# PIC32CX1025SG41064 device description
Architecture: CORTEX-M4; Family: PIC32CX; Series: PIC32CXSG41
Registers are 32-bit, read-write, reset 0x0 unless marked. A register's access mark holds for its fields unless they carry their own. Offsets are from the block's base; [hi:lo] are bit positions; {n}, {i} and the like mark numbered series; 'fields as' and 'values as' point back to an identical list.

## AES — Advanced Encryption Standard
Instances: AES 0x42002400
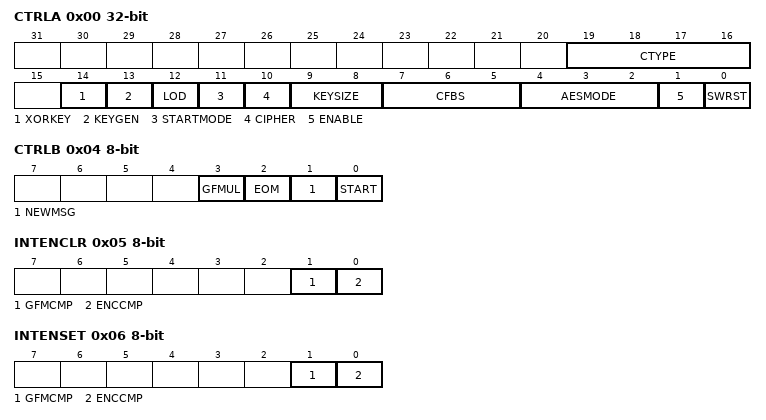
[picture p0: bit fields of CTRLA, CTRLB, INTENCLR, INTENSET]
0x00 CTRLA — Control A
  [19:16] CTYPE — Counter Measure Type
  [14] XORKEY — XOR Key Operation
    0=NONE (No effect); 1=XOR (The user keyword gets XORed with the previous keyword register content.)
  [13] KEYGEN — Last Key Generation
    0=NONE (No effect); 1=LAST (Start Computation of the last NK words of the expanded key)
  [12] LOD — Last Output Data Mode
    0=NONE (No effect); 1=LAST (Start encryption in Last Output Data mode)
  [11] STARTMODE — Start Mode Select
    0=MANUAL (Start Encryption / Decryption in Manual mode); 1=AUTO (Start Encryption / Decryption in Auto mode)
  [10] CIPHER — Cipher Mode
    0=DEC (Decryption); 1=ENC (Encryption)
  [9:8] KEYSIZE — Encryption Key Size
    0=128BIT (128-bit Key for Encryption / Decryption); 1=192BIT (192-bit Key for Encryption / Decryption); 2=256BIT (256-bit Key for Encryption / Decryption)
  [7:5] CFBS — Cipher Feedback Block Size
    0=128BIT (128-bit Input data block for Encryption/Decryption in Cipher Feedback mode); 1=64BIT (64-bit Input data block for Encryption/Decryption in Cipher Feedback mode); 2=32BIT (32-bit Input data block for Encryption/Decryption in Cipher Feedback mode); 3=16BIT (16-bit Input data block for Encryption/Decryption in Cipher Feedback mode); 4=8BIT (8-bit Input data block for Encryption/Decryption in Cipher Feedback mode)
  [4:2] AESMODE — AES Modes of operation
    0=ECB (Electronic code book mode); 1=CBC (Cipher block chaining mode); 2=OFB (Output feedback mode); 3=CFB (Cipher feedback mode); 4=COUNTER (Counter mode); 5=CCM (CCM mode); 6=GCM (Galois counter mode)
  [1] ENABLE
  [0] SWRST — Software Reset
0x04 CTRLB 8-bit — Control B
  [3] GFMUL — GF Multiplication
  [2] EOM — End of message
  [1] NEWMSG — New message
  [0] START — Start Encryption/Decryption
0x05 INTENCLR 8-bit (atomic clear) — Interrupt Enable Clear
  [1] GFMCMP — GF Multiplication Complete Interrupt Enable
  [0] ENCCMP — Encryption Complete Interrupt Enable
0x06 INTENSET 8-bit (atomic set) — Interrupt Enable Set
  fields as INTENCLR
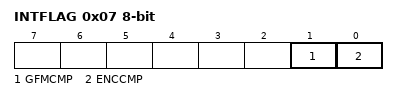
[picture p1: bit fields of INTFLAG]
0x07 INTFLAG 8-bit (atomic clear) — Interrupt Flag Status
  [1] GFMCMP — GF Multiplication Complete
  [0] ENCCMP — Encryption Complete
0x08 DATABUFPTR 8-bit — Data buffer pointer
  [1:0] INDATAPTR — Input Data Pointer
0x09 DBGCTRL 8-bit — Debug control
  [0] DBGRUN — Debug Run
{0xC+4i} KEYWORD[{i}] (i=0..7) wo — Keyword n
  [31:0] KEYWORD — Key Word Value
0x38 INDATA
  [31:0] INDATA — Data Value
{0x3C+4i} INTVECTV[{i}] (i=0..3) wo — Initialisation Vector n
  [31:0] INTVECTV — Initialization Vector Value
{0x5C+4i} HASHKEY[{i}] (i=0..3) — Hash key n
  [31:0] HASHKEY — Hash Key Value
{0x6C+4i} GHASH[{i}] (i=0..3) — Galois Hash n
  [31:0] GHASH — Galois Hash Value
0x80 CIPLEN — Cipher Length
0x84 RANDSEED — Random Seed

## CCL — Configurable Custom Logic
Instances: CCL 0x42003800
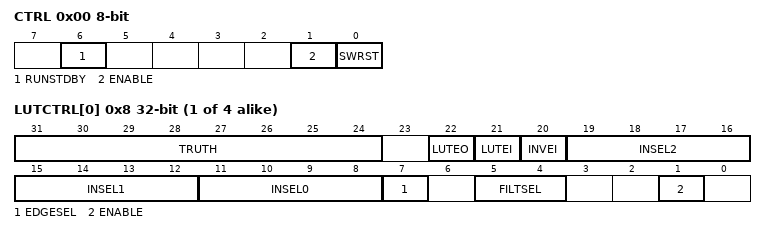
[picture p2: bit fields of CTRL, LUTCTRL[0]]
0x00 CTRL 8-bit — Control
  [6] RUNSTDBY — Run in Standby
    0=DISABLE (Generic clock is not required in standby sleep mode); 1=ENABLE (Generic clock is required in standby sleep mode)
  [1] ENABLE
    0=DISABLE (The peripheral is disabled); 1=ENABLE (The peripheral is enabled)
  [0] SWRST — Software Reset
    0=DISABLE (The peripheral is not reset); 1=ENABLE (The peripheral is reset)
{0x4+i} SEQCTRL[{i}] (i=0..1) 8-bit — SEQ Control x
  [3:0] SEQSEL — Sequential Selection
    0=DISABLE (Sequential logic is disabled); 1=DFF (D flip flop); 2=JK (JK flip flop); 3=LATCH (D latch); 4=RS (RS latch)
{0x8+4i} LUTCTRL[{i}] (i=0..3) — LUT Control x
  [31:24] TRUTH — Truth Value
  [22] LUTEO — LUT Event Output Enable
    0=DISABLE (LUT event output is disabled); 1=ENABLE (LUT event output is enabled)
  [21] LUTEI — LUT Event Input Enable
    0=DISABLE (LUT incoming event is disabled); 1=ENABLE (LUT incoming event is enabled)
  [20] INVEI — Inverted Event Input Enable
    0=DISABLE (Incoming event is not inverted); 1=ENABLE (Incoming event is inverted)
  [19:16] INSEL2 — Input Selection 2
    0=MASK (Masked input); 1=FEEDBACK (Feedback input source); 2=LINK (Linked LUT input source); 3=EVENT (Event input source); 4=IO (I/O pin input source); 5=AC (AC input source); 6=TC (TC input source); 7=ALTTC (Alternate TC input source); 8=TCC (TCC input source); 9=SERCOM (SERCOM input source)
  [15:12] INSEL1 — Input Selection 1
    values as INSEL2
  [11:8] INSEL0 — Input Selection 0
    values as INSEL2
  [7] EDGESEL — Edge Selection
    0=DISABLE (Edge detector is disabled); 1=ENABLE (Edge detector is enabled)
  [5:4] FILTSEL — Filter Selection
    0=DISABLE (Filter disabled); 1=SYNCH (Synchronizer enabled); 2=FILTER (Filter enabled)
  [1] ENABLE — LUT Enable
    0=DISABLE (LUT block is disabled); 1=ENABLE (LUT block is enabled)

## Notices in the file
Copyright (c) 2021 Microchip Technology Inc.
SPDX-License-Identifier: Apache-2.0
Licensed under the Apache License, Version 2.0 (the "License");
you may not use this file except in compliance with the License.
You may obtain a copy of the License at
http://www.apache.org/licenses/LICENSE-2.0
Unless required by applicable law or agreed to in writing, software
distributed under the License is distributed on an "AS IS" BASIS,
WITHOUT WARRANTIES OR CONDITIONS OF ANY KIND, either express or implied.
See the License for the specific language governing permissions and
limitations under the License.
